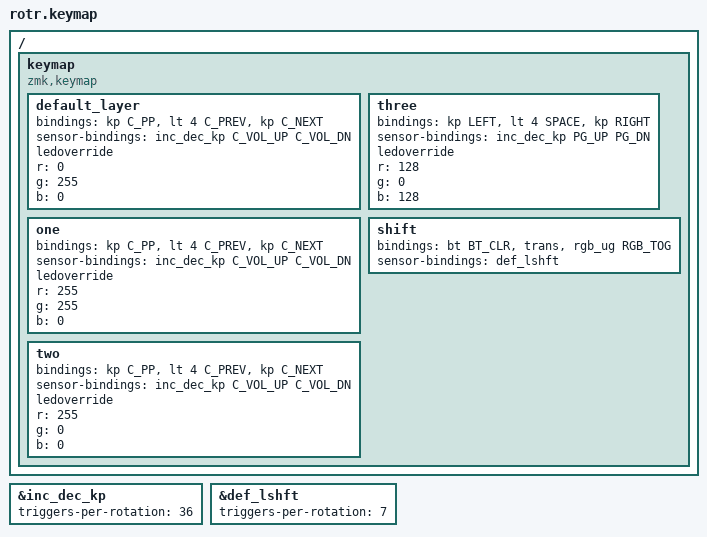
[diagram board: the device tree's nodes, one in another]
#include <behaviors.dtsi>
#include <dt-bindings/zmk/keys.h>
#include <dt-bindings/zmk/rgb.h>
#include <dt-bindings/zmk/bt.h>

&inc_dec_kp {
	triggers-per-rotation = <36>;
};
&def_lshft {
	triggers-per-rotation = <7>;
};

/ {
	keymap {
		compatible = "zmk,keymap";

		default_layer {
			// Green: PLAY/PAUSE | PREV | NEXT
			bindings = <&kp C_PP &lt 4 C_PREV &kp C_NEXT>;
			sensor-bindings = <&inc_dec_kp C_VOL_UP C_VOL_DN>;
			ledoverride; // Default Red
			r = <0>;
			g = <255>;
			b = <0>;
		};
		one {
			// Yellow: PLAY/PAUSE | PREV | NEXT
			bindings = <&kp C_PP &lt 4 C_PREV &kp C_NEXT>;
			sensor-bindings = <&inc_dec_kp C_VOL_UP C_VOL_DN>;
		    	ledoverride; // Default Green
            		r = <255>;
            		g = <255>;
            		b = <0>;
		};
		two {
			// Red: PLAY/PAUSE | PREV | NEXT
			bindings = <&kp C_PP &lt 4 C_PREV &kp C_NEXT>;
			sensor-bindings = <&inc_dec_kp C_VOL_UP C_VOL_DN>;
			ledoverride; // Default Blue
            		r = <255>;
            		g = <0>;
            		b = <0>;
		};
		three {
			// Purple: LEFT ARROW | SPACE BAR | RIGHT ARROW
			bindings = <&kp LEFT &lt 4 SPACE &kp RIGHT>; 
   	  		sensor-bindings = <&inc_dec_kp PG_UP PG_DN>;
			ledoverride;  // Default Yellow
            		r = <128>;
            		g = <0>;
            		b = <128>;
		};
		shift {
			// Layers: Hold MIDDLE & SPIN to cycle layers
			bindings = <&bt BT_CLR &trans &rgb_ug RGB_TOG>;
			sensor-bindings = <&def_lshft>;
		};
	};
};
